# cslr_i2s_001 register map
Vendor: Texas Instruments
Peripheral module from a debugger description file (folder C5535).
Address unit: 16 bits
Registers are 16-bit, read-write, reset 0x0 unless marked. A register's access mark holds for its fields unless they carry their own. Offsets are as the file gives them; lines under a group give offsets from that group; [hi:lo] are bit positions; {n}, {i} and the like mark numbered series; 'fields as' and 'values as' point back to an identical list; <NAME> marks a mode.

## I2S
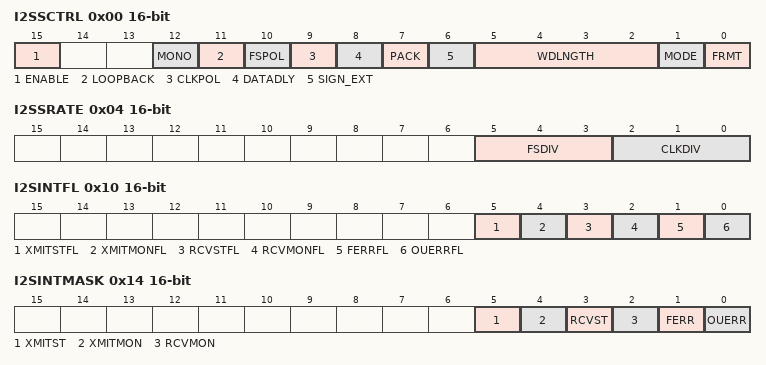
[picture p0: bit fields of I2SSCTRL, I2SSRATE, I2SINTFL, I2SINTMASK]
0x00 I2SSCTRL access not given — Serializer Control Register
  [15] ENABLE rw — Resets or enables the serializer transmission or reception.
    0=CLEAR (The I2S Peripheral (Data xfr, clock generation, and event gen logix) is disabled and held in reset state.); 1=SET (I2S enabled)
  [12] MONO rw — Sets I2S into mono or Stereo mode
    0=CLEAR (Stereo mode); 1=SET (Mono mode)
  [11] LOOPBACK rw — Routes data from transmit shift register back to receive shift register for internal digital loopback
    0=CLEAR (Normal operation, no loopback); 1=SET (Digital loopback mode enabled)
  [10] FSPOL rw — Inverts I2S frame-synchronization polarity
    0=CLEAR (I2S/LJ: Frame-sync pulse is low for left word and high for right word. DSP: Frame-sync is pulsed high); 1=SET (I2S/LJ: Frame-sync pulse is high for left word and low for right word. DSP: Frame-sync is pulsed low)
  [9] CLKPOL rw — controls I2S clock polarity
    0=CLEAR (Receive data is sampled on the rising edge and transmit data shifted on the falling edge of the bit clock.); 1=SET (Receive data is sampled on the falling edge and transmit data shifted on the rising edge of the bit clock)
  [8] DATADLY rw — Sets the I2S receive/transmit data delay.
    0=CLEAR (1 bit data delay); 1=SET (2 bit data delay)
  [7] PACK rw — divides down the generation of interrupts so that data is packed into the 32-bit receive/transmit word registers for each channel (left/right)
    0=CLEAR (Data packing mode disabled); 1=SET (Data packing mode enabled)
  [6] SIGN_EXT rw — enable/disable sign externsionof words
    0=CLEAR (no sign extension); 1=SET (received data is sign extended. Transmit data is expected to be sign extended)
  [5:2] WDLNGTH rw — Choose serializer word length. 0000 = 8-bit data word; 0001 10-bit data &1000 = 32-bit data word
  [1] MODE rw — set the serializer in master or slave mode.
    0=CLEAR (serializer is configured as slave. I2S_BCLK and I2S_FS pins are configured as inputs. The bit-clock and frame-sync signals are derived from an external source and are provided directly to the I2S synchronizer without being further divided.); 1=SET (Serializer is configured as master. I2S_BCLK and FS pins are configured as outputs and driven by the clock generators. The bit clock and drame sync signals are derived from the internal CPU clock.)
  [0] FRMT rw — Sets the derializer data format.
    0=CLEAR (I2S/left-justified format); 1=SET (DSP format)
0x04 I2SSRATE access not given — Sample Rate Generator Register
  [5:3] FSDIV rw — Divider to genreate I2S frame sync clock. The I2S_BCLK is divided down by the configured value to generate the frame sync clock. (no effect when configured as slave.)
    0=DIV8 (Divide by 8); 1=DIV16 (Divide by 16); 2=DIV32 (Divide by 32); 3=DIV64 (Divide by 64); 4=DIV128 (Divide by 128); 5=DIV256 (Divide by 256)
  [2:0] CLKDIV rw — Divider to generate I2S bit clock. The system clock to the I2S is divided down by the configured value to generate the bit clock. (no effect when configured as slave.)
    0=DIV2 (Divide by 2); 1=DIV4 (Divide by 4); 2=DIV8 (Divide by 8); 3=DIV16 (Divide by 16); 4=DIV32 (Divide by 32); 5=DIV64 (Divide by 64); 6=DIV128 (Divide by 128); 7=DIV256 (Divide by 256)
0x08 I2STXLT0 — Transmit Left Data 0
  [15:0] DATA — Transmit Left Data Lower 16 bits
0x09 I2STXLT1 — Transmit Left Data 1
  [15:0] DATA — Transmit Left Data Upper 16 bits
0x0C I2STXRT0 — Transmit Right Data 0
  [15:0] DATA — Transmit Right Data Lower 16 bits
0x0D I2STXRT1 — Transmit Right Data 1
  [15:0] DATA — Transmit Right Data Upper 16 bits
0x10 I2SINTFL access not given — I2S Interrupt Flag register
  [5] XMITSTFL ro — Stereo data transmit flag
    0=CLEAR (no pending stereo transmit interrupt); 1=SET (stereo transmit interrupt pending. Write new data value to I2S Transmit Left and Right data 0 and 1 registers)
  [4] XMITMONFL ro — Mono Data Transmit flag
    0=CLEAR (No pending mono transmit interrupt); 1=SET (Mono transmit interrupt pending. Write new data value to Transmit Left Data 0 and 1 registers)
  [3] RCVSTFL ro — Stereo Data Receive flag
    0=CLEAR (No pending Stereo receive interrupt); 1=SET (stereo receive interrupt pending. Read Receive Left and Right data 0 and 1 registers)
  [2] RCVMONFL ro — Mono Data Receive flag
    0=CLEAR (No pending mono receive interrupt); 1=SET (Mono receive interrupt pending. Read Receive Left data 0 and 1 registers)
  [1] FERRFL ro — Frame Sync Error flag
    0=CLEAR (No Frame-sync errors); 1=SET (Frame-sync error(s) occurred)
  [0] OUERRFL ro — Overrun or Underrun condition
    0=CLEAR (No overrun/under-run errors); 1=SET (The data registers were not read from or written to before the receive/transmit buffer was overwritten.)
0x14 I2SINTMASK access not given — I2S Interrupt Mask Register
  [5] XMITST rw — Enable Stereo Left/right Transmit Data Interrupt
    0=DISABLE (Disable Stereo TX data interrupt); 1=ENABLE (Enable Stereo TX data interrupt)
  [4] XMITMON rw — Enable Mono Left Transmit Data Interrupt
    0=DISABLE (Disable Mono TX data interrupt); 1=ENABLE (Enable Mono TX data Interrupt)
  [3] RCVST rw — Enable Stereo Left/Right Receive Data Interrupt
    0=DISABLE (Disable Stereo RX data interrupt); 1=ENABLE (Enable Stereo RX data interrupt)
  [2] RCVMON rw — Enable Mono Left Receive Data Interrupt
    0=DISABLE (Disable Mono RX data interrupt); 1=ENABLE (Enable Mono RX data Interrupt)
  [1] FERR rw — Enable Frame Sync error
    0=DISABLE (Disable Frame-Sync error interrupt); 1=ENABLE (Enable Frame-Sync error interrupt)
  [0] OUERR rw — Enable Overrun or Underrun condition
    0=DISABLE (Disable Overrun/underrun error interrupt)
0x28 I2SRXLT0 — Receive Left Data 0
  [15:0] DATA — Receive Left Data Lower 16 bits
0x29 I2SRXLT1 — Receive Left Data 1
  [15:0] DATA — Receive Left Data Upper 16 bits
0x2C I2SRXRT0 — Receive Right Data 0
  [15:0] DATA — Receive Right Data Lower 16 bits
0x2D I2SRXRT1 — Receive Right Data 1
  [15:0] DATA — Receive Right Data Upper 16 bits
